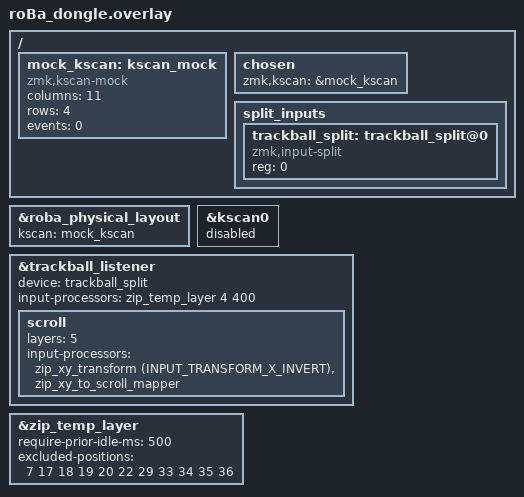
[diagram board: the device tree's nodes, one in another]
#include <dt-bindings/zmk/matrix_transform.h>
#include <dt-bindings/zmk/input_transform.h>
#include <input/processors.dtsi>
#include "roBa.dtsi"

/*
 * Dongle: the central. It has no keys of its own, so a mock kscan stands in
 * for the matrix. The keymap, ZMK Studio, auto mouse layer and scroll
 * handling all live here.
 */
/ {
    mock_kscan: kscan_mock {
        compatible = "zmk,kscan-mock";
        columns = <11>;
        rows = <4>;
        events = <0>;
    };

    chosen {
        zmk,kscan = &mock_kscan;
    };

    /* Receives the trackball events sent by the right half. */
    split_inputs {
        #address-cells = <1>;
        #size-cells = <0>;

        trackball_split: trackball_split@0 {
            compatible = "zmk,input-split";
            reg = <0>;
        };
    };
};

&roba_physical_layout {
    kscan = <&mock_kscan>;
};

/* The dongle has no matrix pins; do not scan the real GPIO matrix. */
&kscan0 {
    status = "disabled";
};

&trackball_listener {
    status = "okay";
    device = <&trackball_split>;

    /* Auto mouse layer (layer 4), off 400ms after the ball stops */
    input-processors = <&zip_temp_layer 4 400>;

    /* Scroll layer (5): ball movement scrolls. X is inverted, as the old
     * driver setting CONFIG_PMW3610_INVERT_SCROLL_X=y did. */
    scroll {
        layers = <5>;
        input-processors = <&zip_xy_transform (INPUT_TRANSFORM_X_INVERT)>,
                           <&zip_xy_to_scroll_mapper>;
    };
};

&zip_temp_layer {
    // Don't enter the mouse layer within 500ms of a key press (typing jiggle)
    require-prior-idle-ms = <500>;
    // Keys that keep the mouse layer on; any other key turns it off at once.
    // 7: scroll (mo 5), 17-20 / 29: mouse buttons,
    // 22 / 33: shift (mt), 34-36: Ctrl / Win / Alt
    excluded-positions = <7 17 18 19 20 22 29 33 34 35 36>;
};
